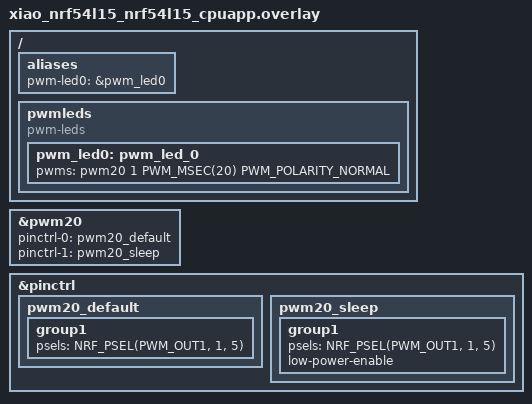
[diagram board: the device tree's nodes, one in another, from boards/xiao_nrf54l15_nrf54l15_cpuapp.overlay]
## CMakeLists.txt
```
# SPDX-License-Identifier: Apache-2.0

cmake_minimum_required(VERSION 3.20.0)
# Boot-time reset reason readout, see lib/reset_reason
list(APPEND ZEPHYR_EXTRA_MODULES ${CMAKE_CURRENT_LIST_DIR}/../lib/reset_reason)
find_package(Zephyr REQUIRED HINTS $ENV{ZEPHYR_BASE})
project(zephyr_pwm_fade)

target_sources(app PRIVATE
  src/main.c
)
```

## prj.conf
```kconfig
CONFIG_PRINTK=y
CONFIG_PWM=y
CONFIG_LOG=y
CONFIG_LOG_PRINTK=y
CONFIG_LOG_MODE_IMMEDIATE=y
CONFIG_PWM_LOG_LEVEL_DBG=y
```

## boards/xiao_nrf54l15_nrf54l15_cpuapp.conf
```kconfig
# Copyright (c) 2024 Nordic Semiconductor ASA
# SPDX-License-Identifier: Apache-2.0


# Enable MBOX for HPF communication (default backend)
#CONFIG_MBOX=y

# Enable IPC service as alternative backend
#CONFIG_IPC_SERVICE=y

# Enable GPIO support (required for pin configuration)
#CONFIG_GPIO=y

# Enable logging for debugging
CONFIG_LOG=y

# Memory and performance optimizations
CONFIG_MAIN_STACK_SIZE=2048
CONFIG_SYSTEM_WORKQUEUE_STACK_SIZE=1024

# Bluetooth Low Energy (DISABLED)
#CONFIG_BT=y
#CONFIG_BT_ZEPHYR_NUS=y
#CONFIG_BT_PERIPHERAL=y
#CONFIG_BT_DEVICE_NAME="POV_Display"

# Nordic UART Service (NUS) (DISABLED)
#CONFIG_BT_NUS=y

# Bluetooth configuration (DISABLED)
#CONFIG_BT_MAX_CONN=1

# PWM for motor control
CONFIG_PWM=y
```

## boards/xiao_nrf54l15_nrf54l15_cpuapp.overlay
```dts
/*
 * Copyright (c) 2024 Nordic Semiconductor ASA
 *
 * SPDX-License-Identifier: Apache-2.0
 * 
 * PWM-capable pins on XIAO nRF54L15:
 * - D0 (P1.04): PWM20 CHAN[0]
 * - D1 (P1.05): PWM20 CHAN[1]
 * - D2 (P1.06): PWM20 CHAN[2]
 * - D3 (P1.07): PWM20 CHAN[3]
 * - D4 (P1.10): PWM20 CHAN[4]
 * - D5 (P1.11): PWM20 CHAN[5]
 * 
 * This sample uses D1 (P1.05) for single LED PWM fade effect
 */

#include <zephyr/dt-bindings/pwm/pwm.h>

/ {
	aliases { 
		pwm-led0 = &pwm_led0;
	};
	
	pwmleds {
		compatible = "pwm-leds";
		pwm_led0: pwm_led_0 {
			pwms = <&pwm20 1 PWM_MSEC(20) PWM_POLARITY_NORMAL>;
		};
	};
};

/* Enable PWM instance 20 */
&pwm20 {
	status = "okay";
	pinctrl-0 = <&pwm20_default>;
	pinctrl-1 = <&pwm20_sleep>;
	pinctrl-names = "default", "sleep";
};

/* Configure PWM Channel 1 on P1.05 (Pin D1) */
&pinctrl {
	pwm20_default: pwm20_default {
		group1 {
			psels = <NRF_PSEL(PWM_OUT1, 1, 5)>;
		};
	};

	pwm20_sleep: pwm20_sleep {
		group1 {
			psels = <NRF_PSEL(PWM_OUT1, 1, 5)>;
			low-power-enable;
		};
	};
};
```

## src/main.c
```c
#include <zephyr/kernel.h>
#include <zephyr/drivers/pwm.h>
#include <zephyr/logging/log.h>

// Register log module
LOG_MODULE_REGISTER(pwm_fade_example, CONFIG_LOG_DEFAULT_LEVEL);

// Define PWM period as 1 millisecond (1,000,000 nanoseconds)
// This corresponds to a 1 kHz PWM frequency
#define PWM_PERIOD_NS 1000000UL // Use UL to ensure unsigned long


#define PWM_LED0_NODE	DT_ALIAS(pwm_led0)

#if DT_NODE_HAS_STATUS(PWM_LED0_NODE, okay)
static const struct pwm_dt_spec led0 = PWM_DT_SPEC_GET(PWM_LED0_NODE);
#else
#error "Unsupported board: pwm-led0 devicetree alias is not defined"
#endif

// Get the PWM LED device defined in the device tree
static const struct pwm_dt_spec led = PWM_DT_SPEC_GET(PWM_LED0_NODE);

int main(void)
{
    int ret;
    uint32_t duty_ns; // PWM duty cycle (in nanoseconds)

    LOG_INF("Starting Zephyr LED fade example...");

    // Check if PWM device is ready
    if (!device_is_ready(led.dev)) {
        LOG_ERR("Error: PWM device %s is not ready", led.dev->name);
        return 0;
    }

    LOG_INF("PWM Period set to %lu ns (1kHz frequency)", PWM_PERIOD_NS);

    while (1) {
        // Fade in from minimum to maximum
        for (int fadeValue = 0; fadeValue <= 255; fadeValue += 3) {
            // Calculate duty cycle (nanoseconds): map Arduino's 0-255 to PWM_PERIOD_NS range
            duty_ns = (PWM_PERIOD_NS * fadeValue) / 255U;

            // Set PWM duty cycle. First parameter is period, second is duty cycle.
            ret = pwm_set_dt(&led, PWM_PERIOD_NS, duty_ns);
            if (ret < 0) {
                LOG_ERR("Error %d: failed to set PWM duty cycle", ret);
                return 0;
            }
            k_msleep(30); // Wait 30 milliseconds
        }

        // Fade out from maximum to minimum
        for (int fadeValue = 255; fadeValue >= 0; fadeValue -= 3) {
            // Calculate duty cycle
            duty_ns = (PWM_PERIOD_NS * fadeValue) / 255U;

            // Set PWM duty cycle
            ret = pwm_set_dt(&led, PWM_PERIOD_NS, duty_ns);
            if (ret < 0) {
                LOG_ERR("Error %d: failed to set PWM duty cycle", ret);
                return 0;
            }
            k_msleep(30); // Wait 30 milliseconds
        }
    }
    return 0;
}
```
